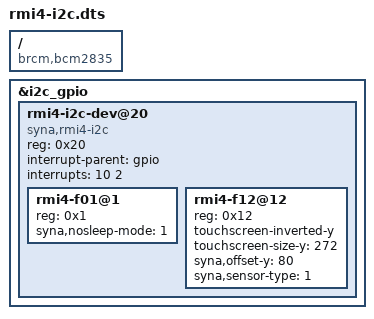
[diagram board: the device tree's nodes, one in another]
/dts-v1/;
/plugin/;

/{
    compatible = "brcm,bcm2835", "brcm,bcm2836", "brcm,bcm2708", "brcm,bcm2709";

    fragment@0
    {
        target = <&i2c_gpio>;
        __overlay__
        {
            #address-cells = <1>;
            #size-cells = <0>;
            status = "okay";

            rmi4-i2c-dev@20
            {
                compatible = "syna,rmi4-i2c";
                reg = <0x20>;
                #address-cells = <1>;
                #size-cells = <0>;
                interrupt-parent = <&gpio>;
                interrupts = <10 2>;

                rmi4-f01@1
                {
                    reg = <0x1>;
                    syna,nosleep-mode = <1>;
                };

                rmi4-f12@12
                {
                    reg = <0x12>;
                    touchscreen-inverted-y;
                    touchscreen-size-y = <272>;
                    syna,offset-y = <80>;
                    syna,sensor-type = <1>;
                };
            };
        };
    };
};
